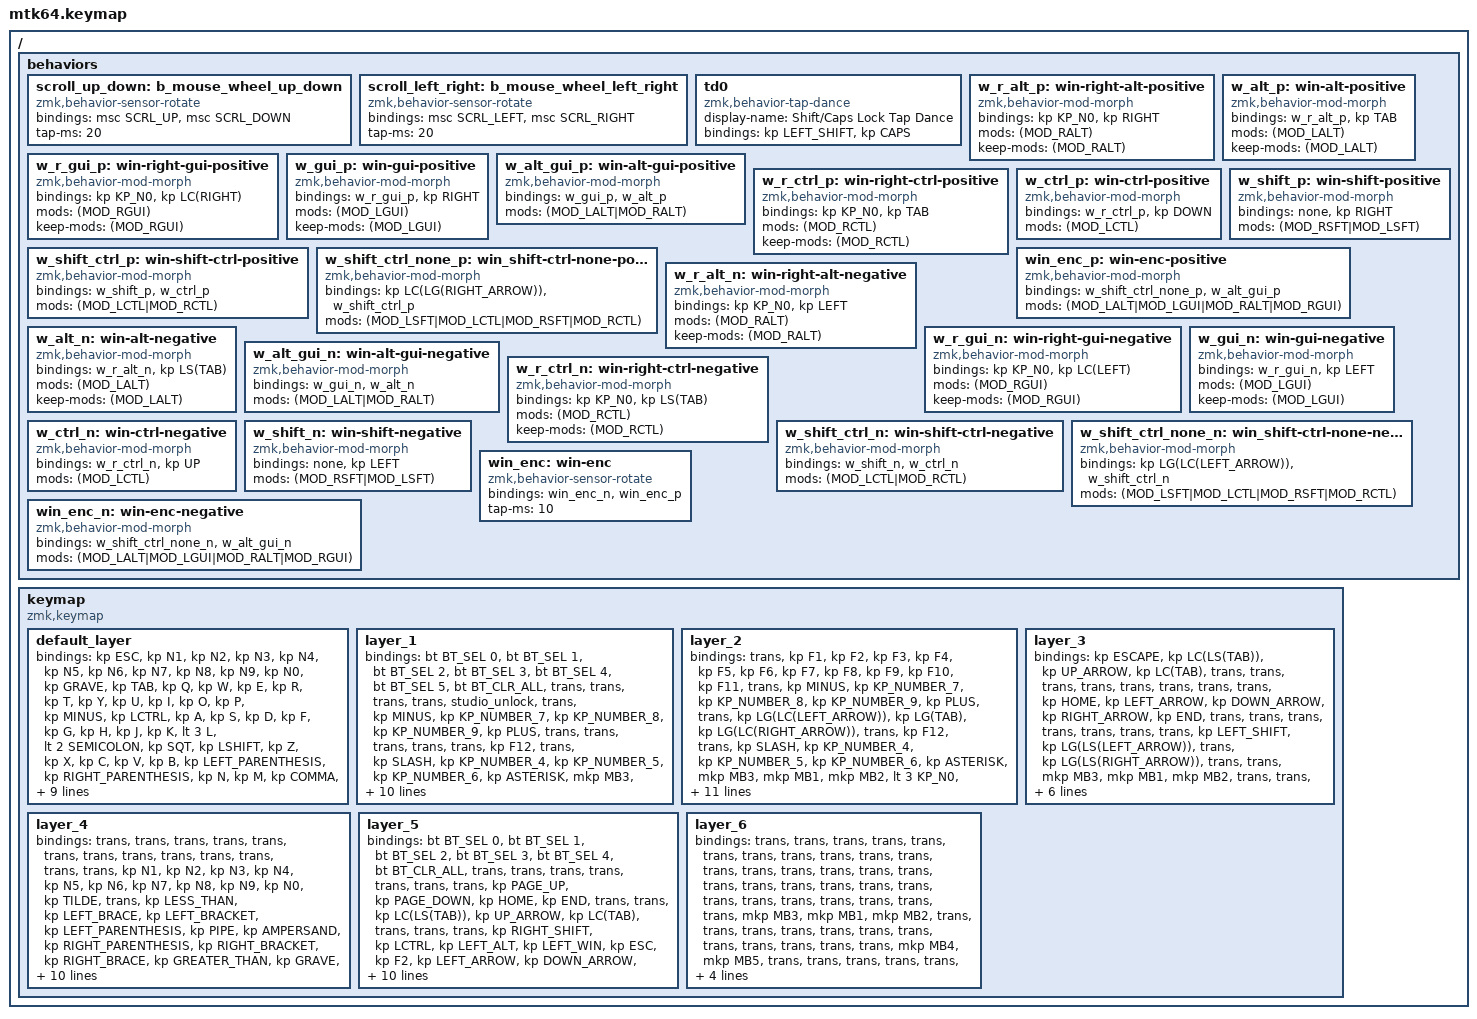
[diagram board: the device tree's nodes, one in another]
#include <behaviors.dtsi>
#include <dt-bindings/zmk/bt.h>
#include <dt-bindings/zmk/keys.h>
#include <dt-bindings/zmk/pointing.h>
#include "keycode_japanese.h"

// スクロール量の設定

#define ZMK_POINTING_DEFAULT_SCRL_VAL 100

/ {
    behaviors {
        // 垂直スクロール用のbehaviorの設定

        scroll_up_down: b_mouse_wheel_up_down {
            compatible = "zmk,behavior-sensor-rotate";
            #sensor-binding-cells = <0>;
            bindings = <&msc SCRL_UP>, <&msc SCRL_DOWN>;

            tap-ms = <20>; // スクロールのタップ時間
        };

        // 水平スクロール用のbehaviorの設定

        scroll_left_right: b_mouse_wheel_left_right {
            compatible = "zmk,behavior-sensor-rotate";
            #sensor-binding-cells = <0>;
            bindings = <&msc SCRL_LEFT>, <&msc SCRL_RIGHT>;

            tap-ms = <20>; // スクロールのタップ時間
        };

        td0: td0 {
            compatible = "zmk,behavior-tap-dance";
            display-name = "Shift/Caps Lock Tap Dance";
            #binding-cells = <0>;
            bindings = <&kp LEFT_SHIFT>, <&kp CAPS>;
        };

        w_r_alt_p: win-right-alt-positive {
            compatible = "zmk,behavior-mod-morph";
            #binding-cells = <0>;
            bindings = <&kp KP_N0>, <&kp RIGHT>;

            mods = <(MOD_RALT)>;
            keep-mods = <(MOD_RALT)>;
        };

        w_alt_p: win-alt-positive {
            compatible = "zmk,behavior-mod-morph";
            #binding-cells = <0>;
            bindings = <&w_r_alt_p>, <&kp TAB>;

            mods = <(MOD_LALT)>;
            keep-mods = <(MOD_LALT)>;
        };

        w_r_gui_p: win-right-gui-positive {
            compatible = "zmk,behavior-mod-morph";
            #binding-cells = <0>;
            bindings = <&kp KP_N0>, <&kp LC(RIGHT)>;

            mods = <(MOD_RGUI)>;
            keep-mods = <(MOD_RGUI)>;
        };

        w_gui_p: win-gui-positive {
            compatible = "zmk,behavior-mod-morph";
            #binding-cells = <0>;
            bindings = <&w_r_gui_p>, <&kp RIGHT>;

            mods = <(MOD_LGUI)>;
            keep-mods = <(MOD_LGUI)>;
        };

        w_alt_gui_p: win-alt-gui-positive {
            compatible = "zmk,behavior-mod-morph";
            #binding-cells = <0>;
            bindings = <&w_gui_p>, <&w_alt_p>;

            mods = <(MOD_LALT|MOD_RALT)>;
        };

        w_r_ctrl_p: win-right-ctrl-positive {
            compatible = "zmk,behavior-mod-morph";
            #binding-cells = <0>;
            bindings = <&kp KP_N0>, <&kp TAB>;

            mods = <(MOD_RCTL)>;
            keep-mods = <(MOD_RCTL)>;
        };

        w_ctrl_p: win-ctrl-positive {
            compatible = "zmk,behavior-mod-morph";
            #binding-cells = <0>;
            bindings = <&w_r_ctrl_p>, <&kp DOWN>;

            mods = <(MOD_LCTL)>;
        };

        w_shift_p: win-shift-positive {
            compatible = "zmk,behavior-mod-morph";
            #binding-cells = <0>;
            bindings = <&none>, <&kp RIGHT>;

            mods = <(MOD_RSFT|MOD_LSFT)>;
        };

        w_shift_ctrl_p: win-shift-ctrl-positive {
            compatible = "zmk,behavior-mod-morph";
            #binding-cells = <0>;
            bindings = <&w_shift_p>, <&w_ctrl_p>;

            mods = <(MOD_LCTL|MOD_RCTL)>;
        };

        w_shift_ctrl_none_p: win_shift-ctrl-none-positive {
            compatible = "zmk,behavior-mod-morph";
            #binding-cells = <0>;
            bindings = <&kp LC(LG(RIGHT_ARROW))>, <&w_shift_ctrl_p>;

            mods = <(MOD_LSFT|MOD_LCTL|MOD_RSFT|MOD_RCTL)>;
        };

        win_enc_p: win-enc-positive {
            compatible = "zmk,behavior-mod-morph";
            #binding-cells = <0>;
            bindings = <&w_shift_ctrl_none_p>, <&w_alt_gui_p>;

            mods = <(MOD_LALT|MOD_LGUI|MOD_RALT|MOD_RGUI)>;
        };

        w_r_alt_n: win-right-alt-negative {
            compatible = "zmk,behavior-mod-morph";
            #binding-cells = <0>;
            bindings = <&kp KP_N0>, <&kp LEFT>;

            mods = <(MOD_RALT)>;
            keep-mods = <(MOD_RALT)>;
        };

        w_alt_n: win-alt-negative {
            compatible = "zmk,behavior-mod-morph";
            #binding-cells = <0>;
            bindings = <&w_r_alt_n>, <&kp LS(TAB)>;

            mods = <(MOD_LALT)>;
            keep-mods = <(MOD_LALT)>;
        };

        w_r_gui_n: win-right-gui-negative {
            compatible = "zmk,behavior-mod-morph";
            #binding-cells = <0>;
            bindings = <&kp KP_N0>, <&kp LC(LEFT)>;

            mods = <(MOD_RGUI)>;
            keep-mods = <(MOD_RGUI)>;
        };

        w_gui_n: win-gui-negative {
            compatible = "zmk,behavior-mod-morph";
            #binding-cells = <0>;
            bindings = <&w_r_gui_n>, <&kp LEFT>;

            mods = <(MOD_LGUI)>;
            keep-mods = <(MOD_LGUI)>;
        };

        w_alt_gui_n: win-alt-gui-negative {
            compatible = "zmk,behavior-mod-morph";
            #binding-cells = <0>;
            bindings = <&w_gui_n>, <&w_alt_n>;

            mods = <(MOD_LALT|MOD_RALT)>;
        };

        w_r_ctrl_n: win-right-ctrl-negative {
            compatible = "zmk,behavior-mod-morph";
            #binding-cells = <0>;
            bindings = <&kp KP_N0>, <&kp LS(TAB)>;

            mods = <(MOD_RCTL)>;
            keep-mods = <(MOD_RCTL)>;
        };

        w_ctrl_n: win-ctrl-negative {
            compatible = "zmk,behavior-mod-morph";
            #binding-cells = <0>;
            bindings = <&w_r_ctrl_n>, <&kp UP>;

            mods = <(MOD_LCTL)>;
        };

        w_shift_n: win-shift-negative {
            compatible = "zmk,behavior-mod-morph";
            #binding-cells = <0>;
            bindings = <&none>, <&kp LEFT>;

            mods = <(MOD_RSFT|MOD_LSFT)>;
        };

        w_shift_ctrl_n: win-shift-ctrl-negative {
            compatible = "zmk,behavior-mod-morph";
            #binding-cells = <0>;
            bindings = <&w_shift_n>, <&w_ctrl_n>;

            mods = <(MOD_LCTL|MOD_RCTL)>;
        };

        w_shift_ctrl_none_n: win_shift-ctrl-none-negative {
            compatible = "zmk,behavior-mod-morph";
            #binding-cells = <0>;
            bindings = <&kp LG(LC(LEFT_ARROW))>, <&w_shift_ctrl_n>;

            mods = <(MOD_LSFT|MOD_LCTL|MOD_RSFT|MOD_RCTL)>;
        };

        win_enc_n: win-enc-negative {
            compatible = "zmk,behavior-mod-morph";
            #binding-cells = <0>;
            bindings = <&w_shift_ctrl_none_n>, <&w_alt_gui_n>;

            mods = <(MOD_LALT|MOD_LGUI|MOD_RALT|MOD_RGUI)>;
        };

        win_enc: win-enc {
            compatible = "zmk,behavior-sensor-rotate";
            #sensor-binding-cells = <0>;
            bindings = <&win_enc_n>, <&win_enc_p>;

            tap-ms = <10>;
        };
    };
};

/ {
    keymap {
        compatible = "zmk,keymap";

        default_layer {
            bindings = <
&kp ESC  &kp N1  &kp N2  &kp N3  &kp N4  &kp N5  &kp N6  &kp N7  &kp N8  &kp N9  &kp N0  &kp GRAVE  &kp TAB  &kp Q  &kp W  &kp E  &kp R  &kp T  &kp Y  &kp U  &kp I  &kp O  &kp P  &kp MINUS  &kp LCTRL  &kp A  &kp S  &kp D  &kp F  &kp G  &kp H  &kp J  &kp K  &lt 3 L  &lt 2 SEMICOLON  &kp SQT  &kp LSHIFT  &kp Z  &kp X  &kp C  &kp V  &kp B  &kp LEFT_PARENTHESIS  &kp RIGHT_PARENTHESIS  &kp N  &kp M  &kp COMMA  &kp PERIOD  &kp SLASH  &mt RIGHT_SHIFT EQUAL  &kp LALT  &kp LGUI  &lt 5 SPACE  &kp TAB  &kp BSPC  &lt 4 ENTER  &kp LEFT_WIN  &kp RIGHT_ALT  &tog 2  &kp ENTER  &kp LG(LC(LEFT_ARROW))  &kp LG(LC(RIGHT_ARROW))  &kp ENTER  &tog 2  &mt LSHIFT LANG2  &mt LCTRL LANG1  &mo 2  &mo 2  &mo 3  &mo 2  &mo 2  &mo 3  &mo 2  &mo 2  &mo 3
            >;

            sensor-bindings = <&scroll_left_right>, <&win_enc>;
        };

        layer_1 {
            bindings = <
&bt BT_SEL 0  &bt BT_SEL 1  &bt BT_SEL 2  &bt BT_SEL 3  &bt BT_SEL 4  &bt BT_SEL 5  &bt BT_CLR_ALL  &trans  &trans  &trans  &trans  &studio_unlock  &trans  &kp MINUS  &kp KP_NUMBER_7  &kp KP_NUMBER_8  &kp KP_NUMBER_9  &kp PLUS  &trans  &trans  &trans  &trans  &trans  &kp F12  &trans  &kp SLASH  &kp KP_NUMBER_4  &kp KP_NUMBER_5  &kp KP_NUMBER_6  &kp ASTERISK  &mkp MB3  &mkp MB1  &mkp MB2  &trans  &trans  &trans  &trans  &mt LEFT_SHIFT KP_NUMBER_0  &kp KP_NUMBER_1  &kp KP_NUMBER_2  &kp KP_NUMBER_3  &kp PERIOD  &kp EQUAL  &trans  &trans  &mkp MB4  &mkp MB5  &trans  &trans  &trans  &trans  &trans  &trans  &trans  &trans  &trans  &trans  &trans  &trans  &trans  &trans  &trans  &trans  &trans  &trans  &trans  &trans  &trans  &trans  &trans  &trans  &trans  &trans  &trans  &trans
            >;
        };

        layer_2 {
            bindings = <
&trans  &kp F1  &kp F2  &kp F3  &kp F4  &kp F5  &kp F6  &kp F7  &kp F8  &kp F9  &kp F10  &kp F11  &trans  &kp MINUS  &kp KP_NUMBER_7  &kp KP_NUMBER_8  &kp KP_NUMBER_9  &kp PLUS  &trans  &kp LG(LC(LEFT_ARROW))  &kp LG(TAB)  &kp LG(LC(RIGHT_ARROW))  &trans  &kp F12  &trans  &kp SLASH  &kp KP_NUMBER_4  &kp KP_NUMBER_5  &kp KP_NUMBER_6  &kp ASTERISK  &mkp MB3  &mkp MB1  &mkp MB2  &lt 3 KP_N0  &trans  &trans  &trans  &mt LEFT_SHIFT KP_NUMBER_0  &kp KP_NUMBER_1  &kp KP_NUMBER_2  &kp KP_NUMBER_3  &kp PERIOD  &kp EQUAL  &trans  &trans  &mkp MB4  &mkp MB5  &trans  &trans  &trans  &trans  &trans  &trans  &trans  &trans  &trans  &trans  &trans  &trans  &trans  &trans  &trans  &trans  &trans  &trans  &trans  &trans  &trans  &trans  &trans  &trans  &trans  &trans  &trans  &trans
            >;

            sensor-bindings = <
                &inc_dec_kp TAB LC(TAB) 
                &inc_dec_kp PG_UP PG_DN
            >;
        };

        layer_3 {
            bindings = <
&kp ESCAPE  &kp LC(LS(TAB))  &kp UP_ARROW  &kp LC(TAB)  &trans  &trans  &trans  &trans  &trans  &trans  &trans  &trans  &kp HOME  &kp LEFT_ARROW  &kp DOWN_ARROW  &kp RIGHT_ARROW  &kp END  &trans  &trans  &trans  &trans  &trans  &trans  &trans  &kp LEFT_SHIFT  &kp LG(LS(LEFT_ARROW))  &trans  &kp LG(LS(RIGHT_ARROW))  &trans  &trans  &mkp MB3  &mkp MB1  &mkp MB2  &trans  &trans  &trans  &trans  &trans  &trans  &trans  &trans  &trans  &trans  &trans  &trans  &mkp MB4  &mkp MB5  &trans  &trans  &trans  &trans  &trans  &trans  &trans  &trans  &trans  &trans  &trans
            >;

            sensor-bindings = <
                &scroll_left_right
                &scroll_up_down
            >;
        };

        layer_4 {
            bindings = <
&trans  &trans  &trans  &trans  &trans  &trans  &trans  &trans  &trans  &trans  &trans  &trans  &trans  &kp N1  &kp N2  &kp N3  &kp N4  &kp N5  &kp N6  &kp N7  &kp N8  &kp N9  &kp N0  &kp TILDE  &trans  &kp LESS_THAN  &kp LEFT_BRACE  &kp LEFT_BRACKET  &kp LEFT_PARENTHESIS  &kp PIPE  &kp AMPERSAND  &kp RIGHT_PARENTHESIS  &kp RIGHT_BRACKET  &kp RIGHT_BRACE  &kp GREATER_THAN  &kp GRAVE  &trans  &kp EXCLAMATION  &kp AT_SIGN  &kp HASH  &kp DOLLAR  &kp PERCENT  &trans  &trans  &kp CARET  &kp PLUS  &kp ASTRK  &kp UNDERSCORE  &kp BACKSLASH  &trans  &trans  &trans  &kp LANG2  &kp LS(TAB)  &trans  &trans  &trans  &trans  &trans  &trans  &trans  &trans  &trans  &trans  &trans  &trans  &trans  &trans  &trans  &trans  &trans  &trans  &trans  &trans  &trans
            >;

            sensor-bindings = <&scroll_left_right>, <&scroll_up_down>;
        };

        layer_5 {
            bindings = <
&bt BT_SEL 0  &bt BT_SEL 1  &bt BT_SEL 2  &bt BT_SEL 3  &bt BT_SEL 4  &bt BT_CLR_ALL  &trans  &trans  &trans  &trans  &trans  &trans  &trans  &kp PAGE_UP  &kp PAGE_DOWN  &kp HOME  &kp END  &trans  &trans  &kp LC(LS(TAB))  &kp UP_ARROW  &kp LC(TAB)  &trans  &trans  &trans  &kp RIGHT_SHIFT  &kp LCTRL  &kp LEFT_ALT  &kp LEFT_WIN  &kp ESC  &kp F2  &kp LEFT_ARROW  &kp DOWN_ARROW  &kp RIGHT_ARROW  &trans  &trans  &trans  &kp LC(Z)  &kp LC(C)  &kp LC(C)  &kp LC(V)  &trans  &trans  &trans  &trans  &kp LG(LC(LEFT_ARROW))  &kp LG(TAB)  &kp LG(LC(RIGHT_ARROW))  &trans  &trans  &trans  &trans  &trans  &trans  &kp DEL  &kp LANG1  &trans  &trans  &trans  &trans  &trans  &trans  &trans  &trans  &trans  &trans  &trans  &trans  &trans  &trans  &trans  &trans  &trans  &trans  &trans
            >;
        };

        layer_6 {
            bindings = <
&trans  &trans  &trans  &trans  &trans  &trans  &trans  &trans  &trans  &trans  &trans  &trans  &trans  &trans  &trans  &trans  &trans  &trans  &trans  &trans  &trans  &trans  &trans  &trans  &trans  &trans  &trans  &trans  &trans  &trans  &mkp MB3  &mkp MB1  &mkp MB2  &trans  &trans  &trans  &trans  &trans  &trans  &trans  &trans  &trans  &trans  &trans  &trans  &mkp MB4  &mkp MB5  &trans  &trans  &trans  &trans  &trans  &trans  &trans  &trans  &trans  &trans  &trans  &trans  &trans  &trans  &trans  &trans  &trans  &trans  &trans  &trans  &trans  &trans  &trans  &trans  &trans  &trans  &trans  &trans
            >;
        };
    };
};
